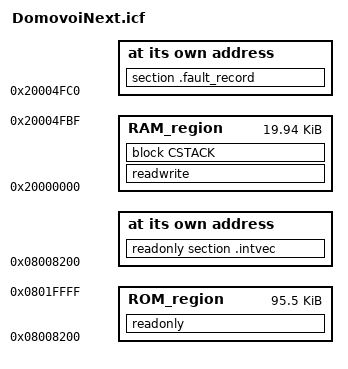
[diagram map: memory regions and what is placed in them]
/*###ICF### Section handled by ICF editor, don't touch! ****/
/*-Editor annotation file-*/
/* IcfEditorFile="$TOOLKIT_DIR$\config\ide\IcfEditor\cortex_v1_0.xml" */
/*-Specials-*/
define symbol __ICFEDIT_intvec_start__ = 0x08008200;
/*-Memory Regions-*/
define symbol __ICFEDIT_region_ROM_start__ = 0x08008200;
define symbol __ICFEDIT_region_ROM_end__   = 0x0801FFFF;
define symbol __ICFEDIT_region_RAM_start__ = 0x20000000;
define symbol __ICFEDIT_region_RAM_end__   = 0x20004FBF;
/*-Sizes-*/
define symbol __ICFEDIT_size_cstack__ = 0xE00;
/**** End of ICF editor section. ###ICF###*/
/* Стек 3,5 КБ (23.10.2026): по STACK USAGE линкера пик 1 312 Б (Release, USB 111) и 1 168 Б
   (ReleaseCustomer) с одним уровнем вложенного разбора через мост, прерывания до 344 Б;
   обновление 1 636 Б идёт с закрытыми прерываниями. Второй уровень вложенности не открывается:
   wifi_locked не отдаёт слот передачи, пока в приёме есть байты. */

define memory mem with size = 4G;
define region ROM_region   = mem:[from __ICFEDIT_region_ROM_start__   to __ICFEDIT_region_ROM_end__];
define region RAM_region   = mem:[from __ICFEDIT_region_RAM_start__   to __ICFEDIT_region_RAM_end__];

define block CSTACK    with alignment = 8, size = __ICFEDIT_size_cstack__   { };

initialize by copy { readwrite };
do not initialize { section .fault_record };
place at address mem:0x20004FC0 { section .fault_record };

place at address mem:__ICFEDIT_intvec_start__ { readonly section .intvec };

place in ROM_region   { readonly };
place in RAM_region   { readwrite,
                        block CSTACK };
